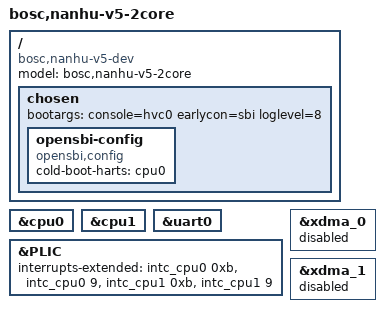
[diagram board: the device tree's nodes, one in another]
// SPDX-License-Identifier: (GPL-2.0 OR MIT)
/* Copyright (c) 2025 BOSC */

/dts-v1/;
#include "nanhu-v5.dtsi"

/ {
	#address-cells = <2>;
	#size-cells = <2>;
	compatible = "bosc,nanhu-v5-dev";
	model = "bosc,nanhu-v5-2core";

	chosen {
		bootargs = "console=hvc0 earlycon=sbi loglevel=8";
		opensbi-config {
		    compatible = "opensbi,config";
		    cold-boot-harts = <&cpu0>;
		};
	};
};

&cpu0 {
	status = "okay";
};

&cpu1 {
	status = "okay";
};

&uart0 {
	status = "okay";
};
&PLIC {

	interrupts-extended =
		<&intc_cpu0  0xb>, <&intc_cpu0	9>,
		<&intc_cpu1  0xb>, <&intc_cpu1 	9>;
};
&xdma_0 {
	status = "disabled";
};
&xdma_1 {
	status = "disabled";
};
